# STM32L4x1 register map
File version: 2.5
CPU: CM4 r0p1, little endian, MPU, FPU, 4 interrupt priority bits
Registers are 32-bit, read-write, reset 0x0 unless marked. A register's access mark holds for its fields unless they carry their own. Offsets are from the block's base; [hi:lo] are bit positions; {n}, {i} and the like mark numbered series; 'fields as' and 'values as' point back to an identical list.

## LCD — Liquid crystal display controller
Base 0x40002400
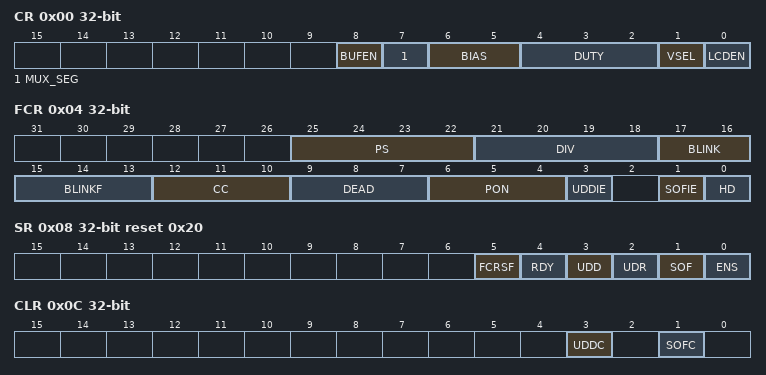
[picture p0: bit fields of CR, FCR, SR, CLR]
0x00 CR — control register
  [8] BUFEN — Voltage output buffer enable
  [7] MUX_SEG — Mux segment enable
  [6:5] BIAS — Bias selector
  [4:2] DUTY — Duty selection
  [1] VSEL — Voltage source selection
  [0] LCDEN — LCD controller enable
0x04 FCR — frame control register
  [25:22] PS — PS 16-bit prescaler
  [21:18] DIV — DIV clock divider
  [17:16] BLINK — Blink mode selection
  [15:13] BLINKF — Blink frequency selection
  [12:10] CC — Contrast control
  [9:7] DEAD — Dead time duration
  [6:4] PON — Pulse ON duration
  [3] UDDIE — Update display done interrupt enable
  [1] SOFIE — Start of frame interrupt enable
  [0] HD — High drive enable
0x08 SR access per field reset 0x20 — status register
  [5] FCRSF ro — LCD Frame Control Register Synchronization flag
  [4] RDY ro — Ready flag
  [3] UDD ro — Update Display Done
  [2] UDR wo — Update display request
  [1] SOF ro — Start of frame flag
  [0] ENS ro
0x0C CLR wo — clear register
  [3] UDDC — Update display done clear
  [1] SOFC — Start of frame flag clear
{0x14+8i} RAM_COM{i} 64-bit (reset mask 0xFFFFFFFF) (i=0..3) — LCD display memory
  [39:0] SEGS — Segment states, one bit per segment, LSB: S00, MSB: S39
{0x14+8i} RAM_COM{i} 64-bit (reset mask 0xFFFFFFFF) (i=4..7) — LCD display memory
  [43:0] SEGS — Segment states, one bit per segment, LSB: S00, MSB: S43

## IWDG — Independent watchdog
Base 0x40003000
0x00 KR 16-bit wo — Key register
  [15:0] KEY — Key value (write only, read 0x0000)
    0x5555=Unlock (Enable access to PR, RLR and WINR registers); 0xAAAA=Feed watchdog with RLR register value; 0xCCCC=Start the watchdog
0x04 PR 16-bit — Prescaler register
  [2:0] PR — Prescaler divider
    0=DivideBy4 (Divider /4); 1=DivideBy8 (Divider /8); 2=DivideBy16 (Divider /16); 3=DivideBy32 (Divider /32); 4=DivideBy64 (Divider /64); 5=DivideBy128 (Divider /128); other=DivideBy256 (Divider /256)
0x08 RLR 16-bit reset 0xFFF — Reload register
  [11:0] RL — Watchdog counter reload value
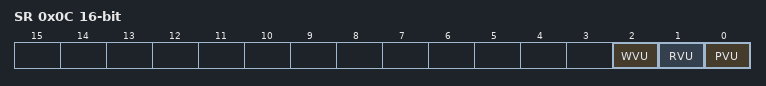
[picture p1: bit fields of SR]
0x0C SR 16-bit ro — Status register
  [2] WVU — Watchdog counter window value update
  [1] RVU — Watchdog counter reload value update
  [0] PVU — Watchdog prescaler value update
0x10 WINR 16-bit reset 0xFFF — Window register
  [11:0] WIN — Watchdog counter window value

## WWDG — System window watchdog
Base 0x40002C00
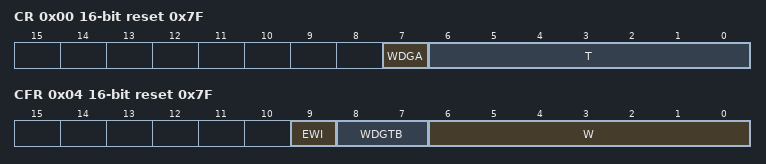
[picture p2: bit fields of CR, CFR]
0x00 CR 16-bit reset 0x7F — Control register
  [7] WDGA — Activation bit
    0=Disabled (Watchdog disabled); 1=Enabled (Watchdog enabled)
  [6:0] T — 7-bit counter (MSB to LSB)
0x04 CFR 16-bit reset 0x7F — Configuration register
  [9] EWI — Early wakeup interrupt
    on write: 1=Enable (interrupt occurs whenever the counter reaches the value 0x40)
  [8:7] WDGTB — Timer base
    0=Div1 (Counter clock (PCLK1 div 4096) div 1); 1=Div2 (Counter clock (PCLK1 div 4096) div 2); 2=Div4 (Counter clock (PCLK1 div 4096) div 4); 3=Div8 (Counter clock (PCLK1 div 4096) div 8)
  [6:0] W — 7-bit window value
0x08 SR 16-bit — Status register
  [0] EWIF write-0-clears — Early wakeup interrupt flag
    on read: 0=Finished (The EWI Interrupt Service Routine has been serviced); 1=Pending (The EWI Interrupt Service Routine has been triggered) | on write: 0=Finished (The EWI Interrupt Service Routine has been serviced)

## COMP — Comparator
Base 0x40010200
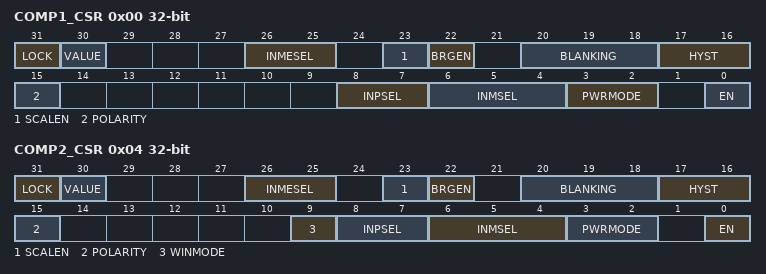
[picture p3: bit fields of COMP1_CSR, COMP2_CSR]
0x00 COMP1_CSR access per field — Comparator 1 control and status register
  [31] LOCK wo — COMP1_CSR register lock bit
    0=Unlocked (Comparator CSR bits are read-write); 1=Locked (Comparator CSR bits are read-only)
  [30] VALUE ro — Comparator 1 output status bit
    0=Low (Comparator output is low); 1=High (Comparator output is high)
  [26:25] INMESEL rw — comparator 1 input minus extended selection bits
    0=PC4; 1=PA0; 2=PA4; 3=PA5
  [23] SCALEN rw — Voltage scaler enable bit
    0=Disabled (Voltage scaler disabled); 1=Enabled (Voltage scaler enabled)
  [22] BRGEN rw — Scaler bridge enable
    0=Disabled (Scaler resistor bridge disabled); 1=Enabled (Scaler resistor bridge enabled)
  [20:18] BLANKING rw — Comparator 1 blanking source selection bits
    0=NoBlanking; 4=TIM1OC5 (TIM15 OC1 selected as blanking source)
  [17:16] HYST rw — Comparator 1 hysteresis selection bits
    0=None (No hysteresis); 1=Low (Low hysteresis); 2=Medium hysteresis; 3=High hysteresis
  [15] POLARITY rw — Comparator 1 polarity selection bit
    0=Normal (Comparator X output value not inverted); 1=Inverted (Comparator X output value inverted)
  [8:7] INPSEL rw — Comparator1 input plus selection bit
    0=PC5 (PC5 connected to input plus); 1=PB2 (PB2 connected to input plus); 2=PA3 (PA3 connected to input plus)
  [6:4] INMSEL rw — Comparator 1 Input Minus connection configuration bit
    0=OneQuarterVRef (1/4 of VRefint); 1=OneHalfVRef (1/2 of VRefint); 2=ThreeQuarterVRef (3/4 of VRefint); 3=VRefint; 4=DAC_CH1 (DAC Channel 1); 5=DAC_CH2 (DAC Channel 2); 6=PB1; 7=Extended (GPIO selected with INMESEL)
  [3:2] PWRMODE rw — Power Mode of the comparator 1
    0=High speed / full power; 1=Medium speed / medium power; 3=Low speed / ultra-low power
  [0] EN rw — Comparator 1 enable bit
    0=Disabled (Comparator X disabled); 1=Enabled (Comparator X enabled)
0x04 COMP2_CSR access per field — Comparator 2 control and status register
  [31] LOCK wo — COMP2_CSR register lock bit
    values as COMP1_CSR.LOCK
  [30] VALUE ro — Comparator 2 output status bit
    values as COMP1_CSR.VALUE
  [26:25] INMESEL rw — comparator 2 input minus extended selection bits
    0=PB7; 1=PA2; 2=PA4; 3=PA5
  [23] SCALEN rw — Voltage scaler enable bit
    values as COMP1_CSR.SCALEN
  [22] BRGEN rw — Scaler bridge enable
    values as COMP1_CSR.BRGEN
  [20:18] BLANKING rw — Comparator 2 blanking source selection bits
    values as COMP1_CSR.BLANKING
  [17:16] HYST rw — Comparator 2 hysteresis selection bits
    values as COMP1_CSR.HYST
  [15] POLARITY rw — Comparator 2 polarity selection bit
    values as COMP1_CSR.POLARITY
  [9] WINMODE rw — Windows mode selection bit
    0=Disabled (COMP2 input plus is not connected to COMP1); 1=Enabled (COMP2 input plus is connected to COMP1)
  [8:7] INPSEL rw — Comparator 2 Input Plus connection configuration bit
    0=PB4 (PB4 connected to input plus); 1=PB6 (PB6 connected to input plus); 2=PA3 (PA3 connected to input plus)
  [6:4] INMSEL rw — Comparator 2 Input Minus connection configuration bit
    0=OneQuarterVRef (1/4 of VRefint); 1=OneHalfVRef (1/2 of VRefint); 2=ThreeQuarterVRef (3/4 of VRefint); 3=VRefint; 4=DAC_CH1 (DAC Channel 1); 5=DAC_CH2 (DAC Channel 2); 6=PB3; 7=Extended (GPIO selected by INMESEL)
  [3:2] PWRMODE rw — Power Mode of the comparator 2
    values as COMP1_CSR.PWRMODE
  [0] EN rw — Comparator 2 enable bit
    values as COMP1_CSR.EN
